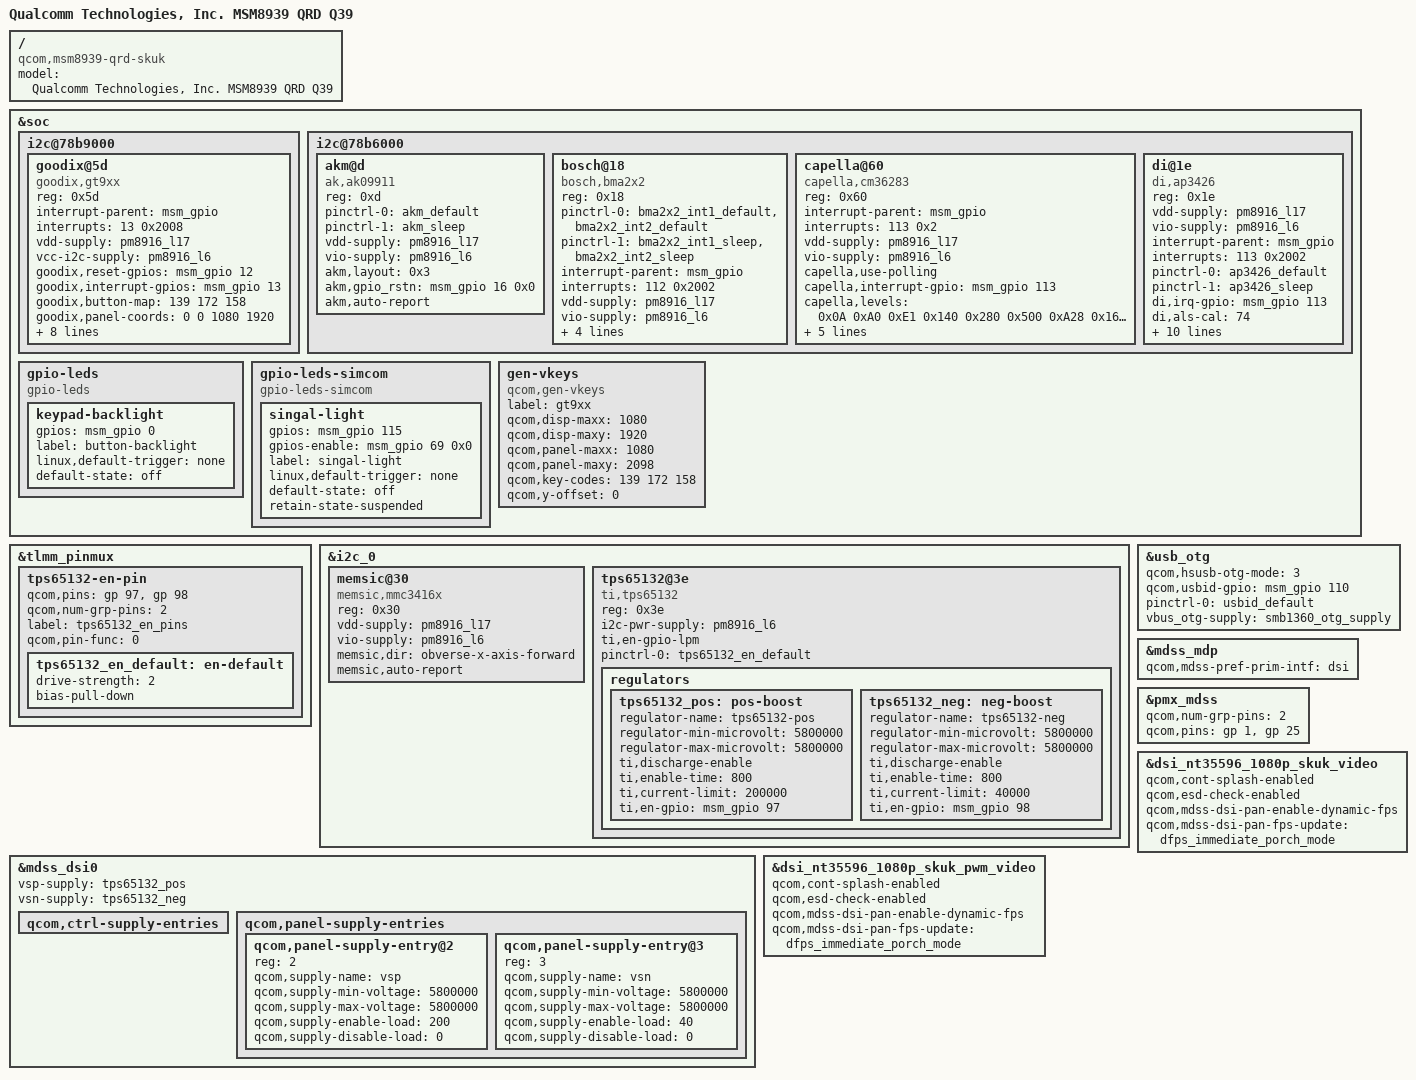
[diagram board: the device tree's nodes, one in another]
/* Copyright (c) 2017, The Linux Foundation. All rights reserved.
 *
 * This program is free software; you can redistribute it and/or modify
 * it under the terms of the GNU General Public License version 2 and
 * only version 2 as published by the Free Software Foundation.
 *
 * This program is distributed in the hope that it will be useful,
 * but WITHOUT ANY WARRANTY; without even the implied warranty of
 * MERCHANTABILITY or FITNESS FOR A PARTICULAR PURPOSE.  See the
 * GNU General Public License for more details.
 */

#include "../dsi-panel-nt35596-1080p-skuk-video.dtsi"
#include "dsi-panel-nt35596-1080p-skuk-pwm-video.dtsi"
#include "dsi-panel-nt35596-auo-1080p-skuk-video.dtsi"
#include "dsi-panel-nt35596-auo-1080p-skuk-pwm-video.dtsi"
#include "dsi-panel-sharp-r61322-1080p-video.dtsi"
#include "dsi-panel-sharp-r61322-pwm-1080p-video.dtsi"
#include "msm8939-camera-sensor-q39.dtsi"
/ {
	model = "Qualcomm Technologies, Inc. MSM8939 QRD Q39";
	compatible = "qcom,msm8939-qrd-skuk", "qcom,msm8939-qrd", "qcom,msm8939", "qcom,qrd";
};

&soc {
	i2c@78b9000 { /* BLSP1 QUP5 */
		goodix@5d {
			compatible = "goodix,gt9xx";
			reg = <0x5d>;
			interrupt-parent = <&msm_gpio>;
			interrupts = <13 0x2008>;
			vdd-supply = <&pm8916_l17>;
			vcc-i2c-supply = <&pm8916_l6>;
			goodix,reset-gpios = <&msm_gpio 12 0x0>;
			goodix,interrupt-gpios = <&msm_gpio 13 0x0>;
			goodix,button-map = <139 172 158>;
			goodix,panel-coords = <0 0 1080 1920>;
			goodix,display-coords = <0 0 1080 1920>;
			goodix,product-id = "9157";
			goodix,num_max_touches = <5>;
			goodix,soft_rst_dly = <20>;
			goodix,fw_name = "gtp_fw.bin";
			goodix,fw-vkey-support;
			goodix,i2c-pull-up;
			goodix,no-force-update;
		};
	};

	i2c@78b6000 { /* BLSP1 QUP2 */
		akm@d {
			compatible = "ak,ak09911";
			reg = <0xd>;
			pinctrl-names = "default", "sleep";
			pinctrl-0 = <&akm_default>;
			pinctrl-1 = <&akm_sleep>;
			vdd-supply = <&pm8916_l17>;
			vio-supply = <&pm8916_l6>;
			akm,layout = <0x3>;
			akm,gpio_rstn = <&msm_gpio 16 0x0>;
			akm,auto-report;
		};

		bosch@18 { /* Accelerometer sensor */
			compatible = "bosch,bma2x2";
			reg = <0x18>;
			pinctrl-names = "bma_default","bma_sleep";
			pinctrl-0 = <&bma2x2_int1_default &bma2x2_int2_default>;
			pinctrl-1 = <&bma2x2_int1_sleep &bma2x2_int2_sleep>;
			interrupt-parent = <&msm_gpio>;
			interrupts = <112 0x2002>;
			vdd-supply = <&pm8916_l17>;
			vio-supply = <&pm8916_l6>;
			bosch,init-interval = <200>;
			bosch,place = <2>;
			bosch,gpio-int1 = <&msm_gpio 112 0x2002>;
			bosch,gpio-int2 = <&msm_gpio 114 0x2002>;
		};

		capella@60 {
			compatible = "capella,cm36283";
			reg = <0x60>;
			interrupt-parent = <&msm_gpio>;
			interrupts = <113 0x2>;
			vdd-supply = <&pm8916_l17>;
			vio-supply = <&pm8916_l6>;
			capella,use-polling;
			capella,interrupt-gpio = <&msm_gpio 113 0x2>;
			capella,levels = <0x0A 0xA0 0xE1 0x140 0x280 0x500 0xA28 0x16A8 0x1F40 					0x2800>;
			capella,ps_close_thd_set = <0x6>;
			capella,ps_away_thd_set = <0x2>;
			capella,ls_cmd = <0x4>;
			capella,ps_conf1_val = <0x0006>;  /*CM36283_PS_ITB_1_2 | CM36283_PS_DR_1_40| CM36283_PS_IT_1T | CM36283_PS_PERS_2 | CM36283_PS_RES_1*/
			capella,ps_conf3_val = <0x3010>;  /* CM36283_PS_MS_NORMAL | CM36283_PS_PROL_255 | CM36283_PS_SMART_PERS_ENABLE, */
		};

		di@1e {
			compatible = "di,ap3426";
			reg = <0x1e>;
			vdd-supply = <&pm8916_l17>;
			vio-supply = <&pm8916_l6>;
			interrupt-parent = <&msm_gpio>;
			interrupts = <113 0x2002>;
			pinctrl-names = "default", "sleep";
			pinctrl-0 = <&ap3426_default>;
			pinctrl-1 = <&ap3426_sleep>;
			di,irq-gpio = <&msm_gpio 113 0x2002>;
			di,als-cal = <74>;
			di,als-gain = <0>;
			di,als-persist = <2>;
			di,ps-gain = <2>;
			di,ps-persist = <2>;
			di,ps-led-driver = <0>;
			di,ps-mean-time = <2>;
			di,ps-integrated-time = <8>;
			di,ps-distance-table = <887 282 111 78 53 46>;
			di,als-sensitivity = <50>;
			di,wakeup-threshold = <0>;
		};
	};

	gpio-leds {
		compatible = "gpio-leds";

		keypad-backlight {
			gpios = <&msm_gpio 0 0x0>;
			label = "button-backlight";
			linux,default-trigger = "none";
			default-state = "off";
		};
	};

	gpio-leds-simcom {
		compatible = "gpio-leds-simcom";

		singal-light {
		gpios = <&msm_gpio 115 0x0>;
		gpios-enable = <&msm_gpio 69 0x0>;
		label = "singal-light";
		linux,default-trigger = "none";
		default-state = "off";
		retain-state-suspended;
		};
	};

	gen-vkeys {
		compatible = "qcom,gen-vkeys";
		label = "gt9xx";
		qcom,disp-maxx = <1080>;
		qcom,disp-maxy = <1920>;
		qcom,panel-maxx = <1080>;
		qcom,panel-maxy = <2098>;
		qcom,key-codes = <139 172 158>;
		qcom,y-offset = <0>;
	};
};

&tlmm_pinmux {

	tps65132-en-pin {
		qcom,pins = <&gp 97>, <&gp 98>;
		qcom,num-grp-pins = <2>;
		label = "tps65132_en_pins";
		qcom,pin-func = <0>;

		tps65132_en_default: en-default {
			drive-strength = <2>;
			bias-pull-down;
		};
	};
};

&i2c_0 { /* BLSP1 QUP2 */
	memsic@30 { /* Magnetic field sensor */
		compatible = "memsic,mmc3416x";
		reg = <0x30>;
		vdd-supply = <&pm8916_l17>;
		vio-supply = <&pm8916_l6>;
		memsic,dir = "obverse-x-axis-forward";
		memsic,auto-report;
	};

	tps65132@3e {
		compatible = "ti,tps65132";
		reg = <0x3e>;
		i2c-pwr-supply = <&pm8916_l6>;
		ti,en-gpio-lpm;
		pinctrl-names = "default";
		pinctrl-0 = <&tps65132_en_default>;

		regulators {
			tps65132_pos: pos-boost {
				regulator-name = "tps65132-pos";
				regulator-min-microvolt = <5800000>;
				regulator-max-microvolt = <5800000>;
				ti,discharge-enable;
				ti,enable-time = <800>;
				ti,current-limit = <200000>;
				ti,en-gpio = <&msm_gpio 97 0>;
			};

			tps65132_neg: neg-boost {
				regulator-name = "tps65132-neg";
				regulator-min-microvolt = <5800000>;
				regulator-max-microvolt = <5800000>;
				ti,discharge-enable;
				ti,enable-time = <800>;
				ti,current-limit = <40000>;
				ti,en-gpio = <&msm_gpio 98 0>;
			};
		};
	};
};

&usb_otg {
       qcom,hsusb-otg-mode = <3>;
       qcom,usbid-gpio = <&msm_gpio 110 0>;
       pinctrl-names = "default";
       pinctrl-0 = <&usbid_default>;
       vbus_otg-supply = <&smb1360_otg_supply>;
};

&mdss_mdp {
      	qcom,mdss-pref-prim-intf = "dsi";
};

&pmx_mdss {
	qcom,num-grp-pins = <2>;
	qcom,pins = <&gp 1>, <&gp 25>;
};

&mdss_dsi0 {
	vsp-supply = <&tps65132_pos>;
	vsn-supply = <&tps65132_neg>;

	qcom,ctrl-supply-entries {
		/delete-node/ qcom,ctrl-supply-entry@0;
	};

	qcom,panel-supply-entries {
		/delete-node/qcom,panel-supply-entry@0;

		qcom,panel-supply-entry@2 {
			reg = <2>;
			qcom,supply-name = "vsp";
			qcom,supply-min-voltage = <5800000>;
			qcom,supply-max-voltage = <5800000>;
			qcom,supply-enable-load = <200>;
			qcom,supply-disable-load = <0>;
		};

		qcom,panel-supply-entry@3 {
			reg = <3>;
			qcom,supply-name = "vsn";
			qcom,supply-min-voltage = <5800000>;
			qcom,supply-max-voltage = <5800000>;
			qcom,supply-enable-load = <40>;
			qcom,supply-disable-load = <0>;
		};
	};
};

&dsi_nt35596_1080p_skuk_video {
	qcom,cont-splash-enabled;
	qcom,esd-check-enabled;
	qcom,mdss-dsi-pan-enable-dynamic-fps;
	qcom,mdss-dsi-pan-fps-update = "dfps_immediate_porch_mode";
};

&dsi_nt35596_1080p_skuk_pwm_video {
	qcom,cont-splash-enabled;
	qcom,esd-check-enabled;
	qcom,mdss-dsi-pan-enable-dynamic-fps;
	qcom,mdss-dsi-pan-fps-update = "dfps_immediate_porch_mode";
};
